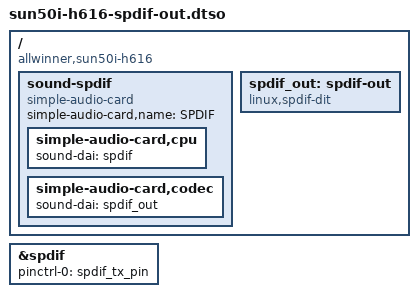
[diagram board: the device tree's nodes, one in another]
/dts-v1/;
/plugin/;

/*
 * S/PDIF (OWA) transmitter on PH4.
 *
 * Orange Pi Zero2: PH4 is pin 5 of the 26-pin header (TWI3-SCK net).
 * Conflicts: i2c3-ph (PH4/PH5). Needs an optical or coaxial S/PDIF
 * transmitter stage on the pin; the SoC drives a 3.3V logic-level
 * biphase signal.
 */

/ {
	compatible = "allwinner,sun50i-h616", "allwinner,sun50i-h618";

	fragment@0 {
		target = <&spdif>;
		__overlay__ {
			pinctrl-names = "default";
			pinctrl-0 = <&spdif_tx_pin>;
			status = "okay";
		};
	};

	fragment@1 {
		target-path = "/";
		__overlay__ {
			sound-spdif {
				compatible = "simple-audio-card";
				simple-audio-card,name = "SPDIF";

				simple-audio-card,cpu {
					sound-dai = <&spdif>;
				};

				simple-audio-card,codec {
					sound-dai = <&spdif_out>;
				};
			};

			spdif_out: spdif-out {
				#sound-dai-cells = <0>;
				compatible = "linux,spdif-dit";
			};
		};
	};
};
